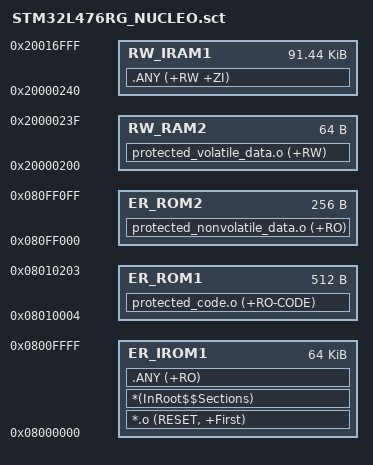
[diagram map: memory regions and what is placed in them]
; *************************************************************
; *** Scatter-Loading Description File generated by uVision ***
; *************************************************************

LR_IROM1 0x08000000 0x00010000  {    ; load region size_region
  ER_IROM1 0x08000000 0x00010000  {  ; load address = execution address
   *.o (RESET, +First)
   *(InRoot$$Sections)
   .ANY (+RO)
  }
  RW_IRAM1 0x20000240 0x00016DC0  {  ; RW data
   .ANY (+RW +ZI)
  }
  ; /**********************************************************/
  ; /*  RW_RAM2: used to locate data in volatile data segment */
  ; /**********************************************************/  
  RW_RAM2 0x20000200 0x0040{  ; RW data
   protected_volatile_data.o (+RW)
  }
}

; /****************************************************************************/
; /*                                                                          */
; /*          LR_ROM1: used to locate code in protected code segment          */
; /*                                                                          */
; /****************************************************************************/
; /* Note that the protected code segment doesn't exactly start at the 
;    starting address used to configure de Firewall.
;    This allows to locate the function used to open the Firewall at the
;    correct address to obey the call gate sequence */
LR_ROM1 0x08010004 0x0000200 {
  ER_ROM1 0x08010004 0x0000200  {  ; load address = execution address
    protected_code.o (+RO-CODE)
	
  }
}

; /****************************************************************************/
; /*                                                                          */
; /*              LR_ROM2: used to locate data in protected                   */
; /*                    non-volatile data segment                             */
; /*                                                                          */
; /*****************************************************************************/
LR_ROM2 0x080FF000 0x0000100 {
  ER_ROM2 0x080FF000 0x0000100  {  
    protected_nonvolatile_data.o (+RO)
	
  }
}

